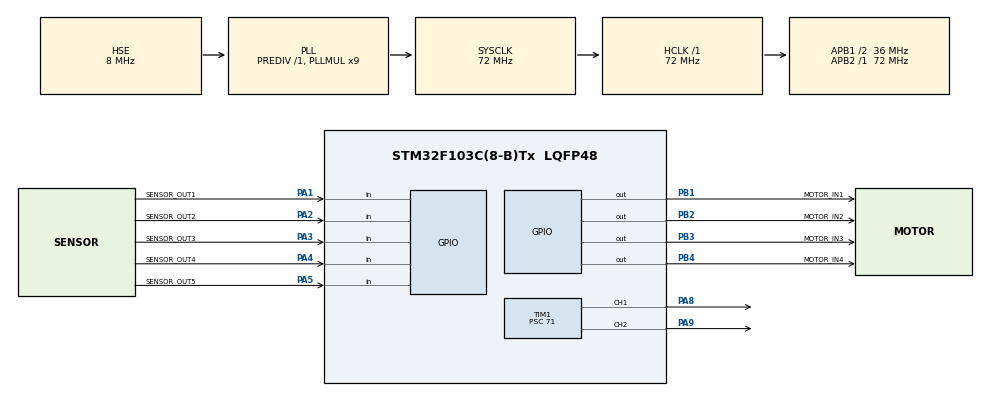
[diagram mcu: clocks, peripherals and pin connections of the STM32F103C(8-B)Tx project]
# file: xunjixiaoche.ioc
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Mcu.Family=STM32F1
Mcu.Name=STM32F103C(8-B)Tx
Mcu.Package=LQFP48
NVIC.PriorityGroup=NVIC_PRIORITYGROUP_4
PA1.GPIO_Label=SENSOR_OUT1
PA1.Signal=GPIO_Input
PA13.Mode=Serial_Wire
PA13.Signal=SYS_JTMS-SWDIO
PA14.Mode=Serial_Wire
PA14.Signal=SYS_JTCK-SWCLK
PA2.GPIO_Label=SENSOR_OUT2
PA2.Signal=GPIO_Input
PA3.GPIO_Label=SENSOR_OUT3
PA3.Signal=GPIO_Input
PA4.GPIO_Label=SENSOR_OUT4
PA4.Signal=GPIO_Input
PA5.GPIO_Label=SENSOR_OUT5
PA5.Signal=GPIO_Input
PA8.Signal=S_TIM1_CH1
PA9.Signal=S_TIM1_CH2
PB1.GPIO_Label=MOTOR_IN1
PB1.Signal=GPIO_Output
PB2.GPIO_Label=MOTOR_IN2
PB2.Signal=GPIO_Output
PB3.GPIO_Label=MOTOR_IN3
PB3.Signal=GPIO_Output
PB4.GPIO_Label=MOTOR_IN4
PB4.Signal=GPIO_Output
PC14-OSC32_IN.Mode=LSE-External-Oscillator
PC14-OSC32_IN.Signal=RCC_OSC32_IN
PC15-OSC32_OUT.Mode=LSE-External-Oscillator
PC15-OSC32_OUT.Signal=RCC_OSC32_OUT
PD0-OSC_IN.Mode=HSE-External-Oscillator
PD0-OSC_IN.Signal=RCC_OSC_IN
PD1-OSC_OUT.Mode=HSE-External-Oscillator
PD1-OSC_OUT.Signal=RCC_OSC_OUT
ProjectManager.HeapSize=0x200
ProjectManager.StackSize=0x400
ProjectManager.TargetToolchain=CMake
RCC.AHBFreq_Value=72000000
RCC.APB1CLKDivider=RCC_HCLK_DIV2
RCC.APB1Freq_Value=36000000
RCC.APB1TimFreq_Value=72000000
RCC.APB2Freq_Value=72000000
RCC.APB2TimFreq_Value=72000000
RCC.HCLKFreq_Value=72000000
RCC.PLLMUL=RCC_PLL_MUL9
RCC.PLLSourceVirtual=RCC_PLLSOURCE_HSE
RCC.SYSCLKFreq_VALUE=72000000
RCC.SYSCLKSource=RCC_SYSCLKSOURCE_PLLCLK
RCC.USBFreq_Value=72000000
SH.S_TIM1_CH1.0=TIM1_CH1,PWM Generation1 CH1
SH.S_TIM1_CH2.0=TIM1_CH2,PWM Generation2 CH2
TIM1.Channel-PWM\ Generation1\ CH1=TIM_CHANNEL_1
TIM1.Channel-PWM\ Generation2\ CH2=TIM_CHANNEL_2
TIM1.Period=9999
TIM1.Prescaler=71
VP_TIM1_VS_ClockSourceINT.Mode=Internal
board=custom

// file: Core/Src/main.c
/* USER CODE BEGIN Header */
/**
  ******************************************************************************
  * @file           : main.c
  * @brief          : Main program body
  ******************************************************************************
  * @attention
  *
  * Copyright (c) 2025 STMicroelectronics.
  * All rights reserved.
  *
  * This software is licensed under terms that can be found in the LICENSE file
  * in the root directory of this software component.
  * If no LICENSE file comes with this software, it is provided AS-IS.
  *
  ******************************************************************************
  */
/* USER CODE END Header */
#include "main.h"

/* USER CODE BEGIN Includes */
#include "motor.h"
#include "track_sensor.h"

/* USER CODE END Includes */

/* USER CODE BEGIN PD */
#define PWM_MAX_VAL        (PWM_PERIOD) // 9999
#define BASE_SPEED         5000         // 基础速度 (0 ~ 9999)
#define TURN_SPEED_LIGHT   2000         // 轻微转向差速
#define TURN_SPEED_HARD    4000         // 大幅转向差速

/* USER CODE END PD */

TIM_HandleTypeDef htim1;

void SystemClock_Config(void);
static void MX_GPIO_Init(void);
static void MX_TIM1_Init(void);

int main(void)
{

  /* MCU Configuration--------------------------------------------------------*/

  /* Reset of all peripherals, Initializes the Flash interface and the Systick. */
  HAL_Init();

  /* Configure the system clock */
  SystemClock_Config();

  /* Initialize all configured peripherals */
  MX_GPIO_Init();
  MX_TIM1_Init();
  /* USER CODE BEGIN 2 */
  Track_Sensor_State_t Sensor_State;
  uint8_t state_byte = 0;

  // 启动两个PWM通道
  HAL_TIM_PWM_Start(&htim1, TIM_CHANNEL_1); // ENA (Left)
  HAL_TIM_PWM_Start(&htim1, TIM_CHANNEL_2); // ENB (Right)

  // 上电延时，等待系统稳定
  Motor_Set_Speed(0, 0); // 确保电机停止
  HAL_Delay(1000);
  /* USER CODE END 2 */

  /* Infinite loop */
  /* USER CODE BEGIN WHILE */
  while (1)
  {
    /* 1. 读取传感器状态 */
    Sensor_State = Track_Sensor_Read();

    /* 2. 组合 5 位为一个字节（左→右 = Out5..Out1） */
    state_byte = (Sensor_State.Out5 << 4) |
                 (Sensor_State.Out4 << 3) |
                 (Sensor_State.Out3 << 2) |
                 (Sensor_State.Out2 << 1) |
                 (Sensor_State.Out1);

    /* 3. 循迹逻辑（黑 = 1, 白 = 0）*/
    switch (state_byte)
    {
        /* ========= ① 直行 ========= */
        case 0b00100:  // 只有中间 Out3=1
        case 0b01110:  // 中间三路都看到黑
        case 0b11111:  // 全黑（十字路口）
            Motor_Set_Speed(BASE_SPEED, BASE_SPEED);
            break;

        /* ========= ② 左偏（右边压线）向左修正 ========= */
        case 0b10010:  // Out2 = 1
        case 0b00011:  // Out2 Out1 = 1
            Motor_Set_Speed(BASE_SPEED - TURN_SPEED_LIGHT,
                            BASE_SPEED + TURN_SPEED_LIGHT);
            break;

        /* ========= ③ 右偏（左边压线）向右修正 ========= */
        case 0b01000:  // Out4 = 1
        case 0b11000:  // Out5 Out4 = 1
            Motor_Set_Speed(BASE_SPEED + TURN_SPEED_LIGHT,
                            BASE_SPEED - TURN_SPEED_LIGHT);
            break;

        /* ========= ④ 严重左偏（最右 1）急左转 ========= */
        case 0b00001:  // Out1 = 1
            Motor_Set_Speed(0,
                            BASE_SPEED + TURN_SPEED_HARD);
            break;

        /* ========= ⑤ 严重右偏（最左 1）急右转 ========= */
        case 0b10000:  // Out5 = 1
            Motor_Set_Speed(BASE_SPEED + TURN_SPEED_HARD,
                            0);
            break;

        /* ========= ⑥ 丢线（全白） ========= */
        case 0b00000:
            Motor_Set_Speed(0, 0);
            break;

        /* ========= ⑦ 未定义情况（稳定） ========= */
        default:
            Motor_Set_Speed(0, 0);
            break;
    }

    HAL_Delay(10);
  }
  /* USER CODE END 3 */
}

void SystemClock_Config(void)
{
  RCC_OscInitTypeDef RCC_OscInitStruct = {0};
  RCC_ClkInitTypeDef RCC_ClkInitStruct = {0};

  /** Initializes the RCC Oscillators according to the specified parameters
  * in the RCC_OscInitTypeDef structure.
  */
  RCC_OscInitStruct.OscillatorType = RCC_OSCILLATORTYPE_HSE;
  RCC_OscInitStruct.HSEState = RCC_HSE_ON;
  RCC_OscInitStruct.HSEPredivValue = RCC_HSE_PREDIV_DIV1;
  RCC_OscInitStruct.HSIState = RCC_HSI_ON;
  RCC_OscInitStruct.PLL.PLLState = RCC_PLL_ON;
  RCC_OscInitStruct.PLL.PLLSource = RCC_PLLSOURCE_HSE;
  RCC_OscInitStruct.PLL.PLLMUL = RCC_PLL_MUL9;
  if (HAL_RCC_OscConfig(&RCC_OscInitStruct) != HAL_OK)
  {
    Error_Handler();
  }

  /** Initializes the CPU, AHB and APB buses clocks
  */
  RCC_ClkInitStruct.ClockType = RCC_CLOCKTYPE_HCLK|RCC_CLOCKTYPE_SYSCLK
                              |RCC_CLOCKTYPE_PCLK1|RCC_CLOCKTYPE_PCLK2;
  RCC_ClkInitStruct.SYSCLKSource = RCC_SYSCLKSOURCE_PLLCLK;
  RCC_ClkInitStruct.AHBCLKDivider = RCC_SYSCLK_DIV1;
  RCC_ClkInitStruct.APB1CLKDivider = RCC_HCLK_DIV2;
  RCC_ClkInitStruct.APB2CLKDivider = RCC_HCLK_DIV1;

  if (HAL_RCC_ClockConfig(&RCC_ClkInitStruct, FLASH_LATENCY_2) != HAL_OK)
  {
    Error_Handler();
  }
}

static void MX_TIM1_Init(void)
{

  TIM_ClockConfigTypeDef sClockSourceConfig = {0};
  TIM_MasterConfigTypeDef sMasterConfig = {0};
  TIM_OC_InitTypeDef sConfigOC = {0};
  TIM_BreakDeadTimeConfigTypeDef sBreakDeadTimeConfig = {0};

  htim1.Instance = TIM1;
  htim1.Init.Prescaler = 71;
  htim1.Init.CounterMode = TIM_COUNTERMODE_UP;
  htim1.Init.Period = 9999;
  htim1.Init.ClockDivision = TIM_CLOCKDIVISION_DIV1;
  htim1.Init.RepetitionCounter = 0;
  htim1.Init.AutoReloadPreload = TIM_AUTORELOAD_PRELOAD_DISABLE;
  if (HAL_TIM_Base_Init(&htim1) != HAL_OK)
  {
    Error_Handler();
  }
  sClockSourceConfig.ClockSource = TIM_CLOCKSOURCE_INTERNAL;
  if (HAL_TIM_ConfigClockSource(&htim1, &sClockSourceConfig) != HAL_OK)
  {
    Error_Handler();
  }
  if (HAL_TIM_PWM_Init(&htim1) != HAL_OK)
  {
    Error_Handler();
  }
  sMasterConfig.MasterOutputTrigger = TIM_TRGO_RESET;
  sMasterConfig.MasterSlaveMode = TIM_MASTERSLAVEMODE_DISABLE;
  if (HAL_TIMEx_MasterConfigSynchronization(&htim1, &sMasterConfig) != HAL_OK)
  {
    Error_Handler();
  }
  sConfigOC.OCMode = TIM_OCMODE_PWM1;
  sConfigOC.Pulse = 0;
  sConfigOC.OCPolarity = TIM_OCPOLARITY_HIGH;
  sConfigOC.OCNPolarity = TIM_OCNPOLARITY_HIGH;
  sConfigOC.OCFastMode = TIM_OCFAST_DISABLE;
  sConfigOC.OCIdleState = TIM_OCIDLESTATE_RESET;
  sConfigOC.OCNIdleState = TIM_OCNIDLESTATE_RESET;
  if (HAL_TIM_PWM_ConfigChannel(&htim1, &sConfigOC, TIM_CHANNEL_1) != HAL_OK)
  {
    Error_Handler();
  }
  if (HAL_TIM_PWM_ConfigChannel(&htim1, &sConfigOC, TIM_CHANNEL_2) != HAL_OK)
  {
    Error_Handler();
  }
  sBreakDeadTimeConfig.OffStateRunMode = TIM_OSSR_DISABLE;
  sBreakDeadTimeConfig.OffStateIDLEMode = TIM_OSSI_DISABLE;
  sBreakDeadTimeConfig.LockLevel = TIM_LOCKLEVEL_OFF;
  sBreakDeadTimeConfig.DeadTime = 0;
  sBreakDeadTimeConfig.BreakState = TIM_BREAK_DISABLE;
  sBreakDeadTimeConfig.BreakPolarity = TIM_BREAKPOLARITY_HIGH;
  sBreakDeadTimeConfig.AutomaticOutput = TIM_AUTOMATICOUTPUT_DISABLE;
  if (HAL_TIMEx_ConfigBreakDeadTime(&htim1, &sBreakDeadTimeConfig) != HAL_OK)
  {
    Error_Handler();
  }
  HAL_TIM_MspPostInit(&htim1);

}

static void MX_GPIO_Init(void)
{
  GPIO_InitTypeDef GPIO_InitStruct = {0};

  /* GPIO Ports Clock Enable */
  __HAL_RCC_GPIOC_CLK_ENABLE();
  __HAL_RCC_GPIOD_CLK_ENABLE();
  __HAL_RCC_GPIOA_CLK_ENABLE();
  __HAL_RCC_GPIOB_CLK_ENABLE();

  /*Configure GPIO pin Output Level */
  HAL_GPIO_WritePin(GPIOB, MOTOR_IN1_Pin|MOTOR_IN2_Pin|MOTOR_IN3_Pin|MOTOR_IN4_Pin, GPIO_PIN_RESET);

  /*Configure GPIO pins : SENSOR_OUT1_Pin SENSOR_OUT2_Pin SENSOR_OUT3_Pin SENSOR_OUT4_Pin
                           SENSOR_OUT5_Pin */
  GPIO_InitStruct.Pin = SENSOR_OUT1_Pin|SENSOR_OUT2_Pin|SENSOR_OUT3_Pin|SENSOR_OUT4_Pin
                          |SENSOR_OUT5_Pin;
  GPIO_InitStruct.Mode = GPIO_MODE_INPUT;
  GPIO_InitStruct.Pull = GPIO_NOPULL;
  HAL_GPIO_Init(GPIOA, &GPIO_InitStruct);

  /*Configure GPIO pins : MOTOR_IN1_Pin MOTOR_IN2_Pin MOTOR_IN3_Pin MOTOR_IN4_Pin */
  GPIO_InitStruct.Pin = MOTOR_IN1_Pin|MOTOR_IN2_Pin|MOTOR_IN3_Pin|MOTOR_IN4_Pin;
  GPIO_InitStruct.Mode = GPIO_MODE_OUTPUT_PP;
  GPIO_InitStruct.Pull = GPIO_NOPULL;
  GPIO_InitStruct.Speed = GPIO_SPEED_FREQ_LOW;
  HAL_GPIO_Init(GPIOB, &GPIO_InitStruct);

}

void Error_Handler(void)
{
  __disable_irq();
  while (1)
  {
  }
}
